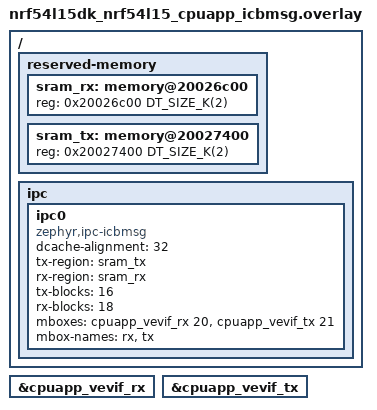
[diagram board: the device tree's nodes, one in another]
/*
 * Copyright (c) 2025 Nordic Semiconductor ASA
 *
 * SPDX-License-Identifier: LicenseRef-Nordic-5-Clause
 */

/ {
	reserved-memory {
		#address-cells = <1>;
		#size-cells = <1>;
		ranges;

		sram_rx: memory@20026c00 {
			reg = <0x20026c00 DT_SIZE_K(2)>;
		};

		sram_tx: memory@20027400 {
			reg = <0x20027400 DT_SIZE_K(2)>;
		};
	};

	ipc {
		ipc0: ipc0 {
			compatible = "zephyr,ipc-icbmsg";
			dcache-alignment = <32>;
			tx-region = <&sram_tx>;
			rx-region = <&sram_rx>;
			tx-blocks = <16>;
			rx-blocks = <18>;
			mboxes = <&cpuapp_vevif_rx 20>, <&cpuapp_vevif_tx 21>;
			mbox-names = "rx", "tx";
			status = "okay";
		};
	};
};

&cpuapp_vevif_rx {
	status = "okay";
};

&cpuapp_vevif_tx {
	status = "okay";
};
